# M55M1 register map
File version: 1.0
Registers are 32-bit, read-write, reset 0x0 unless marked. A register's access mark holds for its fields unless they carry their own. Offsets are from the block's base; [hi:lo] are bit positions; {n}, {i} and the like mark numbered series.

## LPGPIO_NS — LPGPIO Register Map
Base 0x50403000
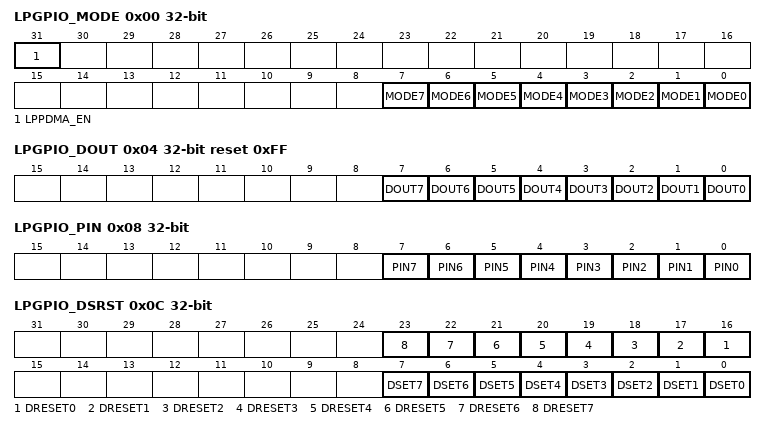
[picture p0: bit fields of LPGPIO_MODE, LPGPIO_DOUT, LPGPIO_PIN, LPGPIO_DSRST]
0x00 LPGPIO_MODE — LPIOn Mode Control
  [31] LPPDMA_EN — LPPDMA Enable Bit. This bit is used to enable LPPDMA to access LPGPIO when chip is in NPD0/1/3.
    0=LPPDMA can't access LPGPIO when chip is in NPD0/1/3; 1=LPPDMA can access LPGPIO when chip is in NPD0/1/3
  [n] MODE{n} (n=0..7) — LPIOn I/O Pin Mode Control. Determine each I/O mode of LPIOn pins.
    0=LPIOn is in Input mode; 1=LPIOn is in Push-pull Output mode
0x04 LPGPIO_DOUT reset 0xFF — LPIOn Data Output Value
  [all] fields
    0=LPIOn will drive Low if the LPIOn pin is configured as Push-pull output mode; 1=LPIOn will drive High if the LPIOn pin is configured as Push-pull output mode
  [n] DOUT{n} (n=0..7) — LPIOn Output Value. Each of these bits controls the status of a LPIOn pin when the LPIOn is configured as Push-pull output mode.
0x08 LPGPIO_PIN ro (reset mask 0xFFFFFF00) — LPIOn Pin Value
  [n] PIN{n} (n=0..7) — LPIOn Pin Value. Each bit of the register reflects the actual status of the respective Pn pin. If the bit is 1, it indicates the corresponding pin status is high; else the pin status is low.
0x0C LPGPIO_DSRST wo — LPIOn Data Output Set and Reset Control
  [n+16] DRESET{n} (n=0..7) — LPIOn Data Ouput Reset Control (Write Only). Writing 1 to each bit can reset LPIOn pin output data to 0. Note 1: This bit field is write only, reading this field will response with 0. Note 2: If DRESET[n] and DSET[n] are both set, DSET[n] has higher pirority. Note 3: Writing 1 to DRESET[n] will make DOUT[n] reflect the reset value.
    0=No action; 1=Reset LPIOn to 0
  [n] DSET{n} (n=0..7) — LPIOn Data Ouput Set Control (Write Only). Writing 1 to each bit can set LPIOn pin output data to 1. Note 1: This bit field is write only, reading this field will response with 0. Note 2: If DRESET[n] and DSET[n] are both set, DSET[n] has higher pirority. Note 3: Writing 1 to DSET[n] will make DOUT[n] reflect the set value.
    0=No action; 1=Reset LPIOn to 1
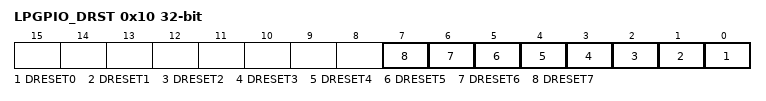
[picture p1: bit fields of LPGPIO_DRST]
0x10 LPGPIO_DRST wo — LPIOn Data Output Reset Control
  [all] fields
    0=No action; 1=Reset LPIOn to 0
  [n] DRESET{n} (n=0..7) — LPIOn Data Ouput Reset Control (Write Only). Writing 1 to each bit can reset LPIOn pin output data to 0. Note 1: This bit field is write only, reading this field will response with 0. Note 2: Writing 1 to DRESET[n] will make DOUT[n] reflect the reset value.

## AWF_NS — AWF Register Map
Base 0x50449000
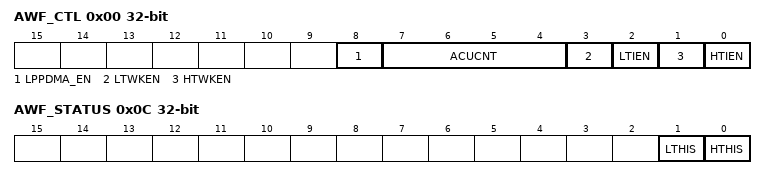
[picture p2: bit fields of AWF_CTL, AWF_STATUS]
0x00 AWF_CTL — AWF Control Register
  [8] LPPDMA_EN — LPPDMA Enable Bit. This bit is used to enable LPPDMA to access AWF when chip is in NPD0/1/3.
    0=LPPDMA can't access AWF when chip is in NPD0/1/3; 1=LPPDMA can access AWF when chip is in NPD0/1/3
  [7:4] ACUCNT — Accumulation Count. The counter defines the acculated data to compare with high threshold and low threshold.The allowed maximum value is 8. If the write value is larger than 8, ACUCNT will become 0.
  [3] LTWKEN — AWF Low Threshold Wake Up Enable Bit
    0=AWF low threshold wake up Disabled; 1=AWF low threshold wake up Enabled
  [2] LTIEN — AWF Low Threshold Interrupt Enable Bit
    0=AWF low threshold interrupt Disabled; 1=AWF low threshold interrupt Enabled
  [1] HTWKEN — AWF High Threshold Wake Up Enable Bit
    0=AWF high threshold wake up Disabled; 1=AWF high threshold wake up Enabled
  [0] HTIEN — AWF High Threshold Interrupt Enable Bit
    0=AWF high threshold interrupt Disabled; 1=AWF high threshold interrupt Enabled
0x04 AWF_HTH — AWF High Threshold Value Register
  [18:0] AWFHTH — AWF High Threshold Value Register. If the accumulated value exceeds the high threshold value, comparing function will activate once set interrupt enable respectively.
0x08 AWF_LTH — AWF Low Threshold Value Register
  [18:0] AWFLTH — AWF Low Threshold Value Register. If the accumulated value is less than the low threshold value, comparing function will activate once set interrupt enable respectively.
0x0C AWF_STATUS
  [1] LTHIS — AWF LTH Interupt Flag. Note: This bit is set to 1 when ACUCNT is not zero and accumulation data is less than LTH. User writes 1 to clear this bit to 0. This bit wil keep 1 if accumulation data is less than LTH after user writes 1 to clear.
    0=AWF LTH interrupt event has not occurred; 1=AWF LTH interrupt event occurs
  [0] HTHIS — AWF HTH Interupt Flag. Note: This bit is set to 1 when ACUCNT is not zero and accumulation data is over than HTH. User writes 1 to clear this bit to 0. This bit will keep 1 if accumulation data is over than HTH after user writes 1 to clear.
    0=AWF HTH interrupt event has not occurred; 1=AWF HTH interrupt event occurs
0x10 AWF_WBINIT — AWF Word Buffer Initial Value Register
  [15:0] WBINIT — AWF Word Buffer Initial Value. Writing this register will update WBINIT into all word registers (AWF_W0 ~ AWF_W7). WBINIT will also be updated into all word registers (AWF_W0 ~ AWF_W7) once ACUCNT is updated.
0x1C AWF_DAT — AWF Data Holding Register
  [15:0] AWFDAT — AWF Data Holding Register. These bits are written by user software and will be filled in circularly from word0 to word[ACUCNT-1].
{0x20+4i} AWF_W{i} ro (i=0..7) — AWF Word Register {i}
  [15:0] WORD — AWF Word Register. Word will accumulate from Word0 to Word[ACUCNT-1], and will compare with AWF_HTH and AWF_LTH.
0x40 AWF_ACUVAL ro — AWF Accumulated Value Register
  [18:0] ACUVAL — AWF Accumulated Value Register. Accumulated value will be accumulated from word0 to word[ACUCNT-1].

## KDF_NS — KDF Register Map
Base 0x50221000
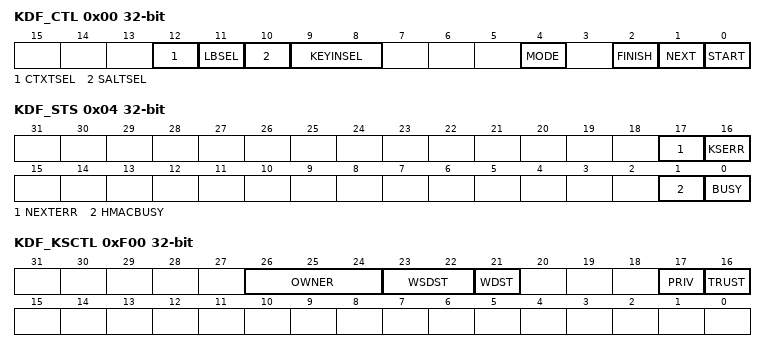
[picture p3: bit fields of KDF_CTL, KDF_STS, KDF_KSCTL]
0x00 KDF_CTL — KDF Control Register
  [12] CTXTSEL — KDF Context Selection
    0=CONTEXT from KDF_CONTEXT register; 1=CONTEXT from random value
  [11] LBSEL — KDF Label Selection
    0=LABEL from KDF_LABEL register; 1=LABEL from random value
  [10] SALTSEL — KDF Salt Selection
    0=SALT from KDF_SALT register; 1=SALT from random value
  [9:8] KEYINSEL — KDF Input Key Source Selection. Note: If KEYINSEL is 01, the NVM key is from KS OTP key 15.
    0=KEYIN from KDF_KEYIN register; 1=KEYIN from NVM (Flash)
  [4] MODE — KDF Mode Selection
    0=HKDF (RFC 5869); 1=KBKDF (NIST SP 800-108)
  [2] FINISH — KDF Next Finish
    0=No effect; 1=Finish generating the next partial key
  [1] NEXT — KDF Next Start
    0=No effect; 1=Start KDF to generate the next partial key only when BUSY is 0. BUSY flag will be set
  [0] START — KDF Start
    0=No operation; 1=Start the operation
0x04 KDF_STS ro — KDF Status Register
  [17] NEXTERR — KDF Next Generation Error Flag
    0=No error; 1=NEXT(KS_CTL[1]) times is greater than KLEN/256
  [16] KSERR — KDF Access Key Store Error Flag
    0=No error; 1=Access Key Store failed
  [1] HMACBUSY — HMAC Busy Flag
    0=HMAC engine is idle or finished; 1=HMAC engine is busy
  [0] BUSY — KDF Busy Flag
    0=KDF is idle or finished; 1=KDF is busy
0x08 KDF_KLEN — KDF Output Key Length Register
  [15:0] KLEN — Output Key Length. The maxinum is 0xFF00 (65280-bit). If KLEN is 0 or greater than the maximum, KDF will not execute.
{0x40+4i} KDF_KEYIN{i} wo (i=0..7) — KDF Input Key Word {i} Register
  [31:0] KEYIN — Input Key. For RFC 5869, input keying material is to be filled in KEYIN. For NIST SP 800-108, KI is to be filled in KEYIN.
{0x80+4i} KDF_KEYOUT{i} ro (i=0..7) — KDF Output Key Word {i} Register
  [31:0] KEYOUT — Output Key. These register bits will be cleared if CPU completes reading key.
{0x100+4i} KDF_SALT{i} wo (i=0..7)
  [31:0] SALT — Salt. These register bits are for RFC 5869.
{0x200+4i} KDF_LABEL{i} wo (i=0..2)
  [31:0] LABEL — Label. For RFC 5869, partial info is to be filled in LABEL according to Figure 6.592. For NIST SP 800-108, Label is to be filled in LABEL.
{0x280+4i} KDF_CTXT{i} wo (i=0..3) — KDF Context {i} Register
  [31:0] CTXT — Context. For RFC 5869, partial info is to be filled in CTXT according to Figure 6.592. For NIST SP 800-108, Context is to be filled in CTXT.
0xF00 KDF_KSCTL wo — KDF Output Key Control Register
  [26:24] OWNER — Write Key Owner Selection Bits
    0=Only for AES use; 1=Only for HMAC engine use; 4=Only for ECC engine use; 5=Only for CPU engine use
  [23:22] WSDST — Write Key Store Destination
    0=Key is written to the SRAM of Key Store; 1=Key is written to the Flash of Key Store
  [21] WDST — Write Key Destination
    0=Key is written to KDF_KEYOUT register; 1=Key is written to Key Store
  [17] PRIV — Write Key Priviledge Selection Bit
    0=Set written key as the non-priviledged key; 1=Set written key as the priviledged key
  [16] TRUST — Write Key Trust Selection Bit
    0=Set written key as the non-secure key; 1=Set written key as the secure key
0xF04 KDF_KSSTS ro — KDF Output Key Status Register
  [4:0] NUM — Key Number. The key number is generated by Key Store.
0xF08 KDF_KSSIZE — KDF Output Key Size Register
  [3:0] SIZE — Key Size Selection Bits
    0=128 bits; 1=163 bits; 2=192 bits; 3=224 bits; 4=233 bits; 5=255 bits; 6=256 bits; 7=283 bits; 8=384 bits; 9=409 bits; 10=512 bits; 11=521 bits; 12=571 bits
